AUTOSAR XML (schema 4.0)
package /ExamplePackage
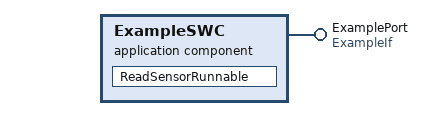
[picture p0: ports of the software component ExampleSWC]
  application sw component type ExampleSWC
    internal behavior ExampleSWC_IB
      runnable ReadSensorRunnable: reentrancy=non-reentrant
        timing event Periodic_10ms: cycle-time={value=10, unit=ms}, maximum-start-delay={value=0, unit=ms}
    provide port ExamplePort: provided-interface=ExampleIf
